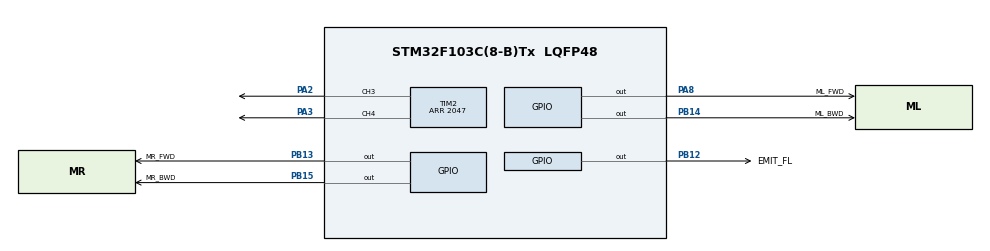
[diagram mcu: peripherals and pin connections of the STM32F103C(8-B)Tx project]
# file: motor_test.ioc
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Mcu.Family=STM32F1
Mcu.Name=STM32F103C(8-B)Tx
Mcu.Package=LQFP48
NVIC.PriorityGroup=NVIC_PRIORITYGROUP_4
PA2.Signal=S_TIM2_CH3
PA3.Signal=S_TIM2_CH4
PA8.GPIO_Label=ML_FWD
PA8.Signal=GPIO_Output
PB12.GPIO_Label=EMIT_FL
PB12.Signal=GPIO_Output
PB13.GPIO_Label=MR_FWD
PB13.Signal=GPIO_Output
PB14.GPIO_Label=ML_BWD
PB14.Signal=GPIO_Output
PB15.GPIO_Label=MR_BWD
PB15.Signal=GPIO_Output
ProjectManager.HeapSize=0x200
ProjectManager.StackSize=0x400
ProjectManager.TargetToolchain=STM32CubeIDE
RCC.APB1Freq_Value=8000000
RCC.APB2Freq_Value=8000000
SH.S_TIM2_CH3.0=TIM2_CH3,PWM Generation3 CH3
SH.S_TIM2_CH4.0=TIM2_CH4,PWM Generation4 CH4
TIM2.AutoReloadPreload=TIM_AUTORELOAD_PRELOAD_ENABLE
TIM2.Channel-PWM\ Generation3\ CH3=TIM_CHANNEL_3
TIM2.Channel-PWM\ Generation4\ CH4=TIM_CHANNEL_4
TIM2.Period=2047
VP_SYS_VS_ND.Mode=No_Debug
VP_TIM2_VS_ClockSourceINT.Mode=Internal
board=custom

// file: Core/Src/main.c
/* USER CODE BEGIN Header */
/**
  ******************************************************************************
  * @file           : main.c
  * @brief          : Main program body
  ******************************************************************************
  * @attention
  *
  * Copyright (c) 2024 STMicroelectronics.
  * All rights reserved.
  *
  * This software is licensed under terms that can be found in the LICENSE file
  * in the root directory of this software component.
  * If no LICENSE file comes with this software, it is provided AS-IS.
  *
  ******************************************************************************
  */
/* USER CODE END Header */
#include "main.h"

TIM_HandleTypeDef htim2;

void SystemClock_Config(void);
static void MX_GPIO_Init(void);
static void MX_TIM2_Init(void);

int main(void)
{

  /* MCU Configuration--------------------------------------------------------*/

  /* Reset of all peripherals, Initializes the Flash interface and the Systick. */
  HAL_Init();

  /* Configure the system clock */
  SystemClock_Config();

  /* Initialize all configured peripherals */
  MX_GPIO_Init();
  MX_TIM2_Init();
  /* USER CODE BEGIN 2 */
  HAL_TIM_PWM_Start(&htim2, TIM_CHANNEL_3);
  HAL_TIM_PWM_Start(&htim2, TIM_CHANNEL_4);
  TIM2->CCR4 = 1350; // right motor
    TIM2->CCR3 = 1350; // left motor

    HAL_GPIO_WritePin(ML_FWD_GPIO_Port, ML_FWD_Pin, 1);
    HAL_GPIO_WritePin(ML_BWD_GPIO_Port, ML_BWD_Pin, 0);
    HAL_GPIO_WritePin(MR_FWD_GPIO_Port, MR_FWD_Pin, 1);
    HAL_GPIO_WritePin(MR_BWD_GPIO_Port, MR_BWD_Pin, 0);

  /* USER CODE END 2 */

  /* Infinite loop */
  while (1)
  {

  }
}

void SystemClock_Config(void)
{
  RCC_OscInitTypeDef RCC_OscInitStruct = {0};
  RCC_ClkInitTypeDef RCC_ClkInitStruct = {0};

  /** Initializes the RCC Oscillators according to the specified parameters
  * in the RCC_OscInitTypeDef structure.
  */
  RCC_OscInitStruct.OscillatorType = RCC_OSCILLATORTYPE_HSI;
  RCC_OscInitStruct.HSIState = RCC_HSI_ON;
  RCC_OscInitStruct.HSICalibrationValue = RCC_HSICALIBRATION_DEFAULT;
  RCC_OscInitStruct.PLL.PLLState = RCC_PLL_NONE;
  if (HAL_RCC_OscConfig(&RCC_OscInitStruct) != HAL_OK)
  {
    Error_Handler();
  }

  /** Initializes the CPU, AHB and APB buses clocks
  */
  RCC_ClkInitStruct.ClockType = RCC_CLOCKTYPE_HCLK|RCC_CLOCKTYPE_SYSCLK
                              |RCC_CLOCKTYPE_PCLK1|RCC_CLOCKTYPE_PCLK2;
  RCC_ClkInitStruct.SYSCLKSource = RCC_SYSCLKSOURCE_HSI;
  RCC_ClkInitStruct.AHBCLKDivider = RCC_SYSCLK_DIV1;
  RCC_ClkInitStruct.APB1CLKDivider = RCC_HCLK_DIV1;
  RCC_ClkInitStruct.APB2CLKDivider = RCC_HCLK_DIV1;

  if (HAL_RCC_ClockConfig(&RCC_ClkInitStruct, FLASH_LATENCY_0) != HAL_OK)
  {
    Error_Handler();
  }
}

static void MX_TIM2_Init(void)
{

  TIM_ClockConfigTypeDef sClockSourceConfig = {0};
  TIM_MasterConfigTypeDef sMasterConfig = {0};
  TIM_OC_InitTypeDef sConfigOC = {0};

  htim2.Instance = TIM2;
  htim2.Init.Prescaler = 0;
  htim2.Init.CounterMode = TIM_COUNTERMODE_UP;
  htim2.Init.Period = 2047;
  htim2.Init.ClockDivision = TIM_CLOCKDIVISION_DIV1;
  htim2.Init.AutoReloadPreload = TIM_AUTORELOAD_PRELOAD_ENABLE;
  if (HAL_TIM_Base_Init(&htim2) != HAL_OK)
  {
    Error_Handler();
  }
  sClockSourceConfig.ClockSource = TIM_CLOCKSOURCE_INTERNAL;
  if (HAL_TIM_ConfigClockSource(&htim2, &sClockSourceConfig) != HAL_OK)
  {
    Error_Handler();
  }
  if (HAL_TIM_PWM_Init(&htim2) != HAL_OK)
  {
    Error_Handler();
  }
  sMasterConfig.MasterOutputTrigger = TIM_TRGO_RESET;
  sMasterConfig.MasterSlaveMode = TIM_MASTERSLAVEMODE_DISABLE;
  if (HAL_TIMEx_MasterConfigSynchronization(&htim2, &sMasterConfig) != HAL_OK)
  {
    Error_Handler();
  }
  sConfigOC.OCMode = TIM_OCMODE_PWM1;
  sConfigOC.Pulse = 0;
  sConfigOC.OCPolarity = TIM_OCPOLARITY_HIGH;
  sConfigOC.OCFastMode = TIM_OCFAST_DISABLE;
  if (HAL_TIM_PWM_ConfigChannel(&htim2, &sConfigOC, TIM_CHANNEL_3) != HAL_OK)
  {
    Error_Handler();
  }
  if (HAL_TIM_PWM_ConfigChannel(&htim2, &sConfigOC, TIM_CHANNEL_4) != HAL_OK)
  {
    Error_Handler();
  }
  HAL_TIM_MspPostInit(&htim2);

}

static void MX_GPIO_Init(void)
{
  GPIO_InitTypeDef GPIO_InitStruct = {0};

  /* GPIO Ports Clock Enable */
  __HAL_RCC_GPIOA_CLK_ENABLE();
  __HAL_RCC_GPIOB_CLK_ENABLE();

  /*Configure GPIO pin Output Level */
  HAL_GPIO_WritePin(GPIOB, EMIT_FL_Pin|MR_FWD_Pin|ML_BWD_Pin|MR_BWD_Pin, GPIO_PIN_RESET);

  /*Configure GPIO pin Output Level */
  HAL_GPIO_WritePin(ML_FWD_GPIO_Port, ML_FWD_Pin, GPIO_PIN_RESET);

  /*Configure GPIO pins : EMIT_FL_Pin MR_FWD_Pin ML_BWD_Pin MR_BWD_Pin */
  GPIO_InitStruct.Pin = EMIT_FL_Pin|MR_FWD_Pin|ML_BWD_Pin|MR_BWD_Pin;
  GPIO_InitStruct.Mode = GPIO_MODE_OUTPUT_PP;
  GPIO_InitStruct.Pull = GPIO_NOPULL;
  GPIO_InitStruct.Speed = GPIO_SPEED_FREQ_LOW;
  HAL_GPIO_Init(GPIOB, &GPIO_InitStruct);

  /*Configure GPIO pin : ML_FWD_Pin */
  GPIO_InitStruct.Pin = ML_FWD_Pin;
  GPIO_InitStruct.Mode = GPIO_MODE_OUTPUT_PP;
  GPIO_InitStruct.Pull = GPIO_NOPULL;
  GPIO_InitStruct.Speed = GPIO_SPEED_FREQ_LOW;
  HAL_GPIO_Init(ML_FWD_GPIO_Port, &GPIO_InitStruct);

}

void Error_Handler(void)
{
  __disable_irq();
  while (1)
  {
  }
}
